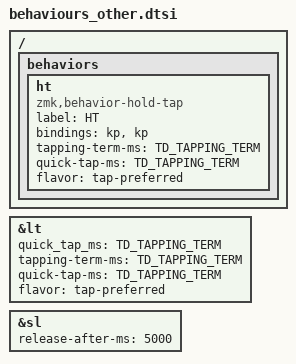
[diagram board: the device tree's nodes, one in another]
#define TD_TAPPING_TERM 300

&lt {
    quick_tap_ms = <TD_TAPPING_TERM>;
    tapping-term-ms = <TD_TAPPING_TERM>;
    quick-tap-ms = <TD_TAPPING_TERM>;
    flavor = "tap-preferred";
};

&sl { release-after-ms = <5000>; };

/ {
    behaviors {

        ht: ht {
            compatible = "zmk,behavior-hold-tap";
            label = "HT";
            bindings = <&kp>, <&kp>;

            #binding-cells = <2>;
            tapping-term-ms = <TD_TAPPING_TERM>;
            quick-tap-ms = <TD_TAPPING_TERM>;
            flavor = "tap-preferred";
        };

    };
};
